# LPC13Uxx register map
File version: 1
CPU: CM3 r2p1, little endian, no MPU, no FPU, 3 interrupt priority bits
Registers are 32-bit, read-write, reset 0x0 unless marked. A register's access mark holds for its fields unless they carry their own. Offsets are from the block's base; [hi:lo] are bit positions; {n}, {i} and the like mark numbered series.

## ADC
Base 0x4001C000
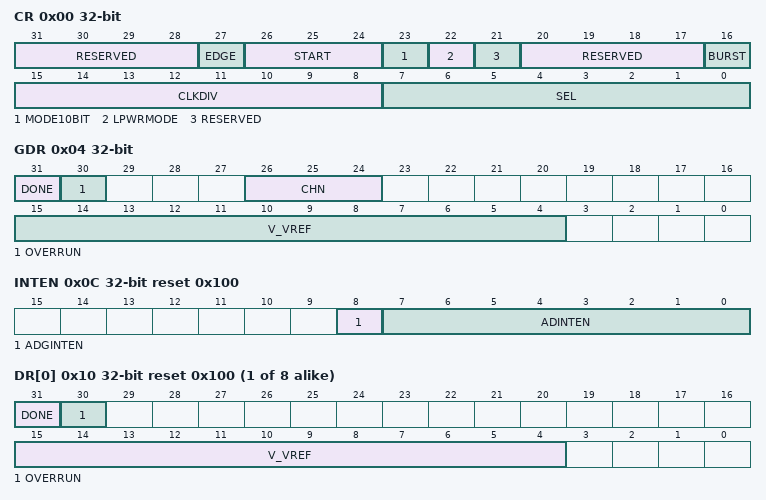
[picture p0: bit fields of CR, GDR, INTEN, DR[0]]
0x00 CR — A/D Control Register. The CR register must be written to select the operating mode before A/D conversion can occur.
  [31:28] RESERVED — Reserved, user software should not write ones to reserved bits. The value read from a reserved bit is not defined.
  [27] EDGE — Edge control. This bit is significant only when the START field contains 010-111.
    0=RISING (Start conversion on a rising edge on the selected CAP/MAT signal.); 1=FALLING (Start conversion on a falling edge on the selected CAP/MAT signal.)
  [26:24] START — When the BURST bit is 0, these bits control whether and when an A/D conversion is started:
    0=NO_START_THIS_VALUE (No start (this value should be used when clearing PDN to 0).); 1=START_CONVERSION_NOW; 2=PIO0_2 (Start conversion when the edge selected by bit 27 occurs on PIO0_2/SSEL/CT16B0_CAP0.); 3=PIO1_5 (Start conversion when the edge selected by bit 27 occurs on PIO1_5/DIR/CT32B0_CAP0.); 4=CT32B0_MAT0 (Start conversion when the edge selected by bit 27 occurs on CT32B0_MAT0\[1\].); 5=CT32B0_MAT1 (Start conversion when the edge selected by bit 27 occurs on CT32B0_MAT1\[1\].); 6=CT16B0_MAT0 (Start conversion when the edge selected by bit 27 occurs on CT16B0_MAT0\[1\].); 7=CT16B0_MAT1 (Start conversion when the edge selected by bit 27 occurs on CT16B0_MAT1\[1\].)
  [23] MODE10BIT — 10-bit conversion rate mode
    0=DISABLE_THE_10_BIT_C (Disable the 10-bit conversion rate mode.); 1=ENABLE_THE_10_BIT_CO (Enable the 10-bit conversion rate mode with high conversion rate.The A/D resolution is reduced to 10 bits (the two LSB of the conversion result will be forced to 0). The clock rate (set via the CLKDIV field) can be doubled to up to 31 MHz to achieve a conversion rate of up to one million samples per second.)
  [22] LPWRMODE — Low-power mode
    0=DISABLE_THE_LOW_POWE (Disable the low-power ADC mode. The analog circuitry remains activated when no conversions are requested.); 1=ENABLE_THE_LOW_POWER (Enable the low-power ADC mode. The analog circuitry is automatically powered-down when no conversions are taking place. When any (hardware or software) triggering event is detected, the analog circuitry is enabled. After the required start-up time, the requested conversion will be launched. Once the conversion completes, the analog-circuitry will again be powered-down provided no further conversions are pending. This mode will NOT power-up the A/D if the ADC is powered down (ADC_PD bit in the PDRUNCFG register is HIGH) or if the part is in Deep-sleep, Power-down, or Deep power-down mode.)
  [21] RESERVED — Reserved, user software should not write ones to reserved bits. The value read from a reserved bit is not defined.
  [20:17] RESERVED — Reserved, user software should not write ones to reserved bits. The value read from a reserved bit is not defined.
  [16] BURST — Burst mode If BURST is set to 1, the ADGINTEN bit in the INTEN register (Table 327) must be set to 0.
    0=SOFTWARE_CONTROLLED_ (Software-controlled mode: Conversions are software-controlled and require 31 clocks.); 1=HARDWARE_SCAN_MODE_ (Hardware scan mode: The AD converter does repeated conversions at the rate selected by the CLKS field, scanning (if necessary) through the pins selected by ones in the SEL field. The first conversion after the start corresponds to the least-significant bit set to 1 in the SEL field, then the next higher bits (pins) set to one are scanned if applicable. Repeated conversions can be terminated by clearing this bit, but the conversion in progress when this bit is cleared will be completed. Important: START bits must be 000 when BURST = 1, or conversions will not start.)
  [15:8] CLKDIV — The main clock (PCLK_ADC) is divided by (this value plus one) to produce the clock for the A/D converter. The clock should be less than or equal to 15.5 MHz(12-bit mode) or 31 MHz (10-bit mode) in software-controlled mode (BURST bit = 0).. Typically, software should program the smallest value in this field that yields a clock of 15.5 MHz or slightly less, but in certain cases (such as a high-impedance analog source) a slower clock may be desirable.
  [7:0] SEL — Selects which of the AD7:0 pins is (are) to be sampled and converted. Bit 0 selects Pin AD0, bit 1 selects pin AD1,..., and bit 7 selects pin AD7. In software-controlled mode (BURST = 0), only one channel can be selected, i.e. only one of these bits should be 1. In hardware scan mode (BURST = 1), any numbers of channels can be selected, i.e any or all bits can be set to 1. If all bits are set to 0, channel 0 is selected automatically (SEL = 0x01).
0x04 GDR reset not defined — A/D Global Data Register. Contains the result of the most recent A/D conversion.
  [31] DONE — This bit is set to 1 when an A/D conversion completes. It is cleared when this register is read and when the ADCR is written. If the ADCR is written while a conversion is still in progress, this bit is set and a new conversion is started.
  [30] OVERRUN — This bit is 1 in burst mode if the results of one or more conversions was (were) lost and overwritten before the conversion that produced the result in the V_VREF bits.
  [26:24] CHN — These bits contain the channel from which the result bits V_VREF were converted.
  [15:4] V_VREF — When DONE is 1, this field contains a binary fraction representing the voltage on the ADn pin selected by the SEL field, divided by the voltage on the VDD pin or as it falls within the range of VREFP to VREFN. Zero in the field indicates that the voltage on the ADn pin was less than, equal to, or close to that on VSS/VREFN, while 0xFFF indicates that the voltage on ADn was close to, equal to, or greater than that on VDD/VREFP.
0x0C INTEN reset 0x100 — A/D Interrupt Enable Register. This register contains enable bits that allow the DONE flag of each A/D channel to be included or excluded from contributing to the generation of an A/D interrupt.
  [8] ADGINTEN — When 1, enables the global DONE flag in ADDR to generate an interrupt. When 0, only the individual A/D channels enabled by ADINTEN 7:0 will generate interrupts. This bit must be set to 0 in burst mode (BURST = 1 in the CR register).
  [7:0] ADINTEN — These bits allow control over which A/D channels generate interrupts for conversion completion. When bit 0 is one, completion of a conversion on A/D channel 0 will generate an interrupt, when bit 1 is one, completion of a conversion on A/D channel 1 will generate an interrupt, etc.
{0x10+4i} DR[{i}] (i=0..7) reset 0x100 — A/D Channel N Data Register. This register contains the result of the most recent conversion completed on channel n
  [31] DONE — This bit is set to 1 when an A/D conversion completes. It is cleared when this register is read.
  [30] OVERRUN — This bit is 1 in burst mode if the results of one or more conversions was (were) lost and overwritten before the conversion that produced the result in the V_VREF bits.This bit is cleared by reading this register.
  [15:4] V_VREF — When DONE is 1, this field contains a binary fraction representing the voltage on the ADn pin as it falls within the range of VREFP to VREFN. Zero in the field indicates that the voltage on the ADn pin was less than, equal to, or close to that on VREFN/VSS, while 0xFFF indicates that the voltage on AD input was close to, equal to, or greater than that on VREFP/VDD.
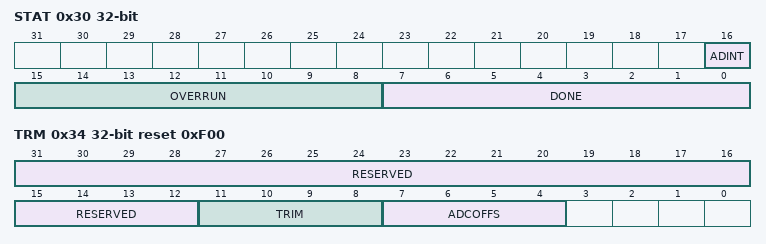
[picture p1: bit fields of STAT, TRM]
0x30 STAT ro — A/D Status Register. This register contains DONE and OVERRUN flags for all of the A/D channels, as well as the A/D interrupt flag.
  [16] ADINT — This bit is the A/D interrupt flag. It is one when any of the individual A/D channel Done flags is asserted and enabled to contribute to the A/D interrupt via the ADINTEN register.
  [15:8] OVERRUN — These bits mirror the OVERRRUN status flags that appear in the result register for each A/D channel n. Reading ADSTAT allows checking the status of all A/D channels simultaneously.
  [7:0] DONE — These bits mirror the DONE status flags that appear in the result register for each A/D channel n.
0x34 TRM reset 0xF00 — A/D trim register
  [31:12] RESERVED — Reserved, user software should not write ones to reserved bits. The value read from a reserved bit is not defined.
  [11:8] TRIM — Written-to by boot code. Can not be overwritten by the user. These bits are locked after boot code write.
  [7:4] ADCOFFS — Offset trim bits for ADC operation. Initialized by the boot code. Can be overwritten by the user.
